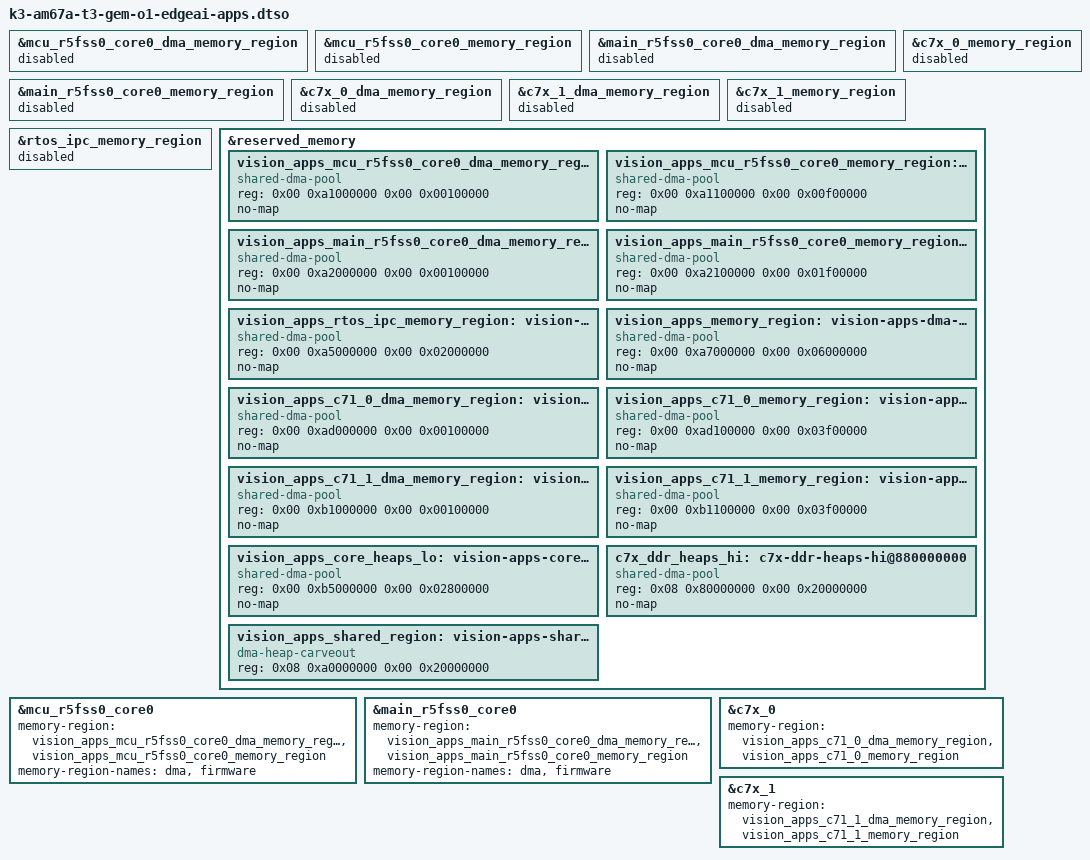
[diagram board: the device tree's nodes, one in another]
// SPDX-License-Identifier: GPL-2.0
/*
 * EdgeAI (vision-apps) memory map overlay for T3 Gemstone O1
 *
 * The base device tree reserves the TI ipc-echo carveout layout, which is what
 * the plain remoteproc IPC firmware expects. The TI EdgeAI / vision-apps
 * firmware builds link against a completely different layout: the C7x DSPs load
 * at 0xad100000 and 0xb1100000 with 63 MiB each, and the stack additionally
 * needs shared DMA heaps for TIDL buffers.
 *
 * Without this overlay, loading the vision-apps firmware fails with:
 *   remoteproc0: bad phdr da 0xad100000 mem 0x8c
 *
 * Apply this overlay only when running the TI EdgeAI stack. The ipc-echo
 * firmware will not work while it is applied.
 *
 * Copyright (C) 2019 Texas Instruments Incorporated - https://www.ti.com/
 * Copyright (C) 2026 T3 Gemstone - https://t3gemstone.org/
 */

/dts-v1/;
/plugin/;

/* Disable the ipc-echo carveouts that this overlay replaces. */
&mcu_r5fss0_core0_dma_memory_region {
	status = "disabled";
};

&mcu_r5fss0_core0_memory_region {
	status = "disabled";
};

&main_r5fss0_core0_dma_memory_region {
	status = "disabled";
};

&main_r5fss0_core0_memory_region {
	status = "disabled";
};

&c7x_0_dma_memory_region {
	status = "disabled";
};

&c7x_0_memory_region {
	status = "disabled";
};

&c7x_1_dma_memory_region {
	status = "disabled";
};

&c7x_1_memory_region {
	status = "disabled";
};

&rtos_ipc_memory_region {
	status = "disabled";
};

&reserved_memory {
	#address-cells = <2>;
	#size-cells = <2>;

	vision_apps_mcu_r5fss0_core0_dma_memory_region: vision-apps-r5f-dma-memory@a1000000 {
		compatible = "shared-dma-pool";
		reg = <0x00 0xa1000000 0x00 0x00100000>;
		no-map;
	};

	vision_apps_mcu_r5fss0_core0_memory_region: vision-apps-r5f-memory@a1100000 {
		compatible = "shared-dma-pool";
		reg = <0x00 0xa1100000 0x00 0x00f00000>;
		no-map;
	};

	vision_apps_main_r5fss0_core0_dma_memory_region: vision-apps-r5f-dma-memory@a2000000 {
		compatible = "shared-dma-pool";
		reg = <0x00 0xa2000000 0x00 0x00100000>;
		no-map;
	};

	vision_apps_main_r5fss0_core0_memory_region: vision-apps-r5f-memory@a2100000 {
		compatible = "shared-dma-pool";
		reg = <0x00 0xa2100000 0x00 0x01f00000>;
		no-map;
	};

	vision_apps_rtos_ipc_memory_region: vision-apps-rtos-ipc-memory-region@a5000000 {
		compatible = "shared-dma-pool";
		reg = <0x00 0xa5000000 0x00 0x02000000>;
		no-map;
	};

	vision_apps_memory_region: vision-apps-dma-memory@a7000000 {
		compatible = "shared-dma-pool";
		reg = <0x00 0xa7000000 0x00 0x06000000>;
		no-map;
	};

	vision_apps_c71_0_dma_memory_region: vision-apps-c71-dma-memory@ad000000 {
		compatible = "shared-dma-pool";
		reg = <0x00 0xad000000 0x00 0x00100000>;
		no-map;
	};

	vision_apps_c71_0_memory_region: vision-apps-c71_0-memory@ad100000 {
		compatible = "shared-dma-pool";
		reg = <0x00 0xad100000 0x00 0x03f00000>;
		no-map;
	};

	vision_apps_c71_1_dma_memory_region: vision-apps-c71_1-dma-memory@b1000000 {
		compatible = "shared-dma-pool";
		reg = <0x00 0xb1000000 0x00 0x00100000>;
		no-map;
	};

	vision_apps_c71_1_memory_region: vision-apps-c71_1-memory@b1100000 {
		compatible = "shared-dma-pool";
		reg = <0x00 0xb1100000 0x00 0x03f00000>;
		no-map;
	};

	vision_apps_core_heaps_lo: vision-apps-core-heap-memory-lo@b5000000 {
		compatible = "shared-dma-pool";
		reg = <0x00 0xb5000000 0x00 0x02800000>;
		no-map;
	};

	c7x_ddr_heaps_hi: c7x-ddr-heaps-hi@880000000 {
		compatible = "shared-dma-pool";
		reg = <0x08 0x80000000 0x00 0x20000000>;
		no-map;
	};

	vision_apps_shared_region: vision-apps-shared-memories@8a0000000 {
		compatible = "dma-heap-carveout";
		reg = <0x08 0xa0000000 0x00 0x20000000>;
	};
};

&mcu_r5fss0_core0 {
	memory-region = <&vision_apps_mcu_r5fss0_core0_dma_memory_region>,
			<&vision_apps_mcu_r5fss0_core0_memory_region>;
	memory-region-names = "dma", "firmware";
};

&main_r5fss0_core0 {
	memory-region = <&vision_apps_main_r5fss0_core0_dma_memory_region>,
			<&vision_apps_main_r5fss0_core0_memory_region>;
	memory-region-names = "dma", "firmware";
};

&c7x_0 {
	memory-region = <&vision_apps_c71_0_dma_memory_region>,
			<&vision_apps_c71_0_memory_region>;
};

&c7x_1 {
	memory-region = <&vision_apps_c71_1_dma_memory_region>,
			<&vision_apps_c71_1_memory_region>;
};
